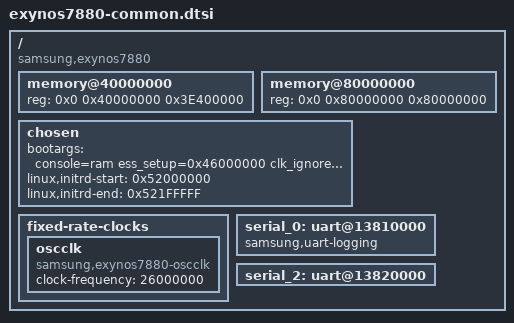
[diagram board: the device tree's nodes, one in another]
/*
 * SAMSUNG Exynos7880 A5/A7 common boot description
 *
 * Copyright (c) 2015 Samsung Electronics Co., Ltd.
 *		http://www.samsung.com
 *
 * This program is free software; you can redistribute it and/or modify
 * it under the terms of the GNU General Public License version 2 as
 * published by the Free Software Foundation.
*/

#include "exynos7880-rmem.dtsi"
#include "exynos7880.dtsi"
#include "modem-ss325ap-pdata.dtsi"

/ {
	compatible = "samsung,exynos7880", "samsung,universal7880";

	memory@40000000 {
		device_type = "memory";
		reg = <0x0 0x40000000 0x3E400000>;
	};

	memory@80000000 {
		device_type = "memory";
		reg = <0x0 0x80000000 0x80000000>;
	};

	chosen {
		bootargs = "console=ram ess_setup=0x46000000 clk_ignore_unused androidboot.hardware=samsungexynos7880 firmware_class.path=/vendor/firmware reserve-fimc=0 androidboot.debug_level=0x4948 androidboot.selinux=permissive";
		linux,initrd-start = <0x52000000>;
		linux,initrd-end = <0x521FFFFF>;
	};

	fixed-rate-clocks {
		oscclk {
			compatible = "samsung,exynos7880-oscclk";
			clock-frequency = <26000000>;
		};
	};

	serial_0: uart@13810000 {
		samsung,uart-logging;
		status = "okay";
	};

	serial_2: uart@13820000 {
		status = "okay";
	};
};
